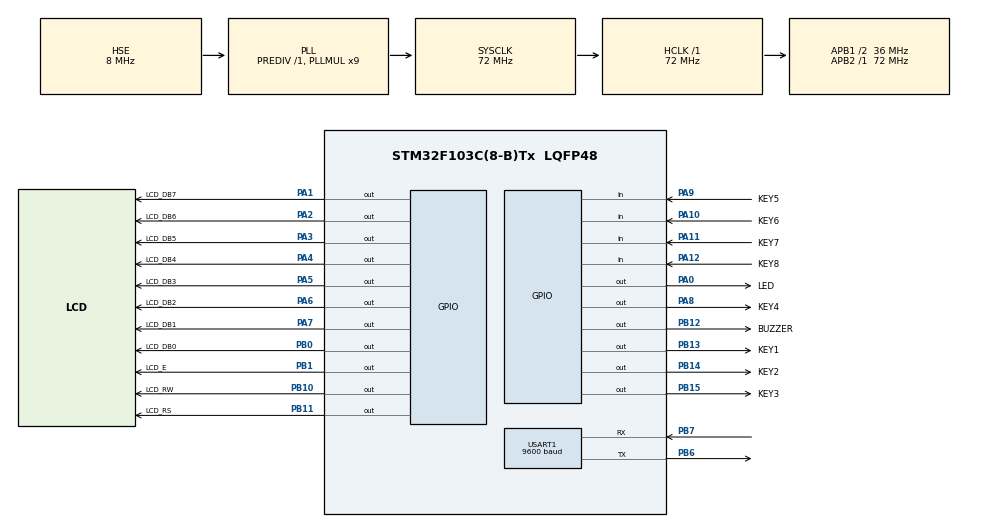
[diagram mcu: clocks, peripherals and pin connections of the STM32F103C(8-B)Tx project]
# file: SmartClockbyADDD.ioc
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Dma.Request0=USART1_RX
Dma.Request1=USART1_TX
Dma.USART1_RX.0.Direction=DMA_PERIPH_TO_MEMORY
Dma.USART1_RX.0.Instance=DMA1_Channel5
Dma.USART1_RX.0.MemDataAlignment=DMA_MDATAALIGN_BYTE
Dma.USART1_RX.0.MemInc=DMA_MINC_ENABLE
Dma.USART1_RX.0.Mode=DMA_NORMAL
Dma.USART1_RX.0.PeriphDataAlignment=DMA_PDATAALIGN_BYTE
Dma.USART1_RX.0.PeriphInc=DMA_PINC_DISABLE
Dma.USART1_RX.0.Priority=DMA_PRIORITY_LOW
Dma.USART1_TX.1.Direction=DMA_MEMORY_TO_PERIPH
Dma.USART1_TX.1.Instance=DMA1_Channel4
Dma.USART1_TX.1.MemDataAlignment=DMA_MDATAALIGN_BYTE
Dma.USART1_TX.1.MemInc=DMA_MINC_ENABLE
Dma.USART1_TX.1.Mode=DMA_NORMAL
Dma.USART1_TX.1.PeriphDataAlignment=DMA_PDATAALIGN_BYTE
Dma.USART1_TX.1.PeriphInc=DMA_PINC_DISABLE
Dma.USART1_TX.1.Priority=DMA_PRIORITY_LOW
Mcu.Family=STM32F1
Mcu.Name=STM32F103C(8-B)Tx
Mcu.Package=LQFP48
NVIC.DMA1_Channel4_IRQn=true\:0\:0\:false\:false\:true\:false\:true\:true
NVIC.DMA1_Channel5_IRQn=true\:0\:0\:false\:false\:true\:false\:true\:true
NVIC.PriorityGroup=NVIC_PRIORITYGROUP_4
NVIC.TIM4_IRQn=true\:0\:0\:false\:false\:true\:true\:true\:true
NVIC.USART1_IRQn=true\:0\:0\:false\:false\:true\:true\:true\:true
PA0-WKUP.GPIO_Label=LED
PA0-WKUP.GPIO_ModeDefaultOutputPP=GPIO_MODE_OUTPUT_OD
PA0-WKUP.GPIO_PuPd=GPIO_NOPULL
PA0-WKUP.Signal=GPIO_Output
PA1.GPIO_Label=LCD_DB7
PA1.Signal=GPIO_Output
PA10.GPIO_Label=KEY6
PA10.GPIO_PuPd=GPIO_PULLUP
PA10.Signal=GPIO_Input
PA11.GPIO_Label=KEY7
PA11.GPIO_PuPd=GPIO_PULLUP
PA11.Signal=GPIO_Input
PA12.GPIO_Label=KEY8
PA12.GPIO_PuPd=GPIO_PULLUP
PA12.Signal=GPIO_Input
PA13.Mode=Serial_Wire
PA13.Signal=SYS_JTMS-SWDIO
PA14.Mode=Serial_Wire
PA14.Signal=SYS_JTCK-SWCLK
PA2.GPIO_Label=LCD_DB6
PA2.Signal=GPIO_Output
PA3.GPIO_Label=LCD_DB5
PA3.Signal=GPIO_Output
PA4.GPIO_Label=LCD_DB4
PA4.Signal=GPIO_Output
PA5.GPIO_Label=LCD_DB3
PA5.Signal=GPIO_Output
PA6.GPIO_Label=LCD_DB2
PA6.Signal=GPIO_Output
PA7.GPIO_Label=LCD_DB1
PA7.Signal=GPIO_Output
PA8.GPIO_Label=KEY4
PA8.Signal=GPIO_Output
PA9.GPIO_Label=KEY5
PA9.GPIO_PuPd=GPIO_PULLUP
PA9.Signal=GPIO_Input
PB0.GPIO_Label=LCD_DB0
PB0.Signal=GPIO_Output
PB1.GPIO_Label=LCD_E
PB1.Signal=GPIO_Output
PB10.GPIO_Label=LCD_RW
PB10.Signal=GPIO_Output
PB11.GPIO_Label=LCD_RS
PB11.Signal=GPIO_Output
PB12.GPIO_Label=BUZZER
PB12.PinState=GPIO_PIN_SET
PB12.Signal=GPIO_Output
PB13.GPIO_Label=KEY1
PB13.Signal=GPIO_Output
PB14.GPIO_Label=KEY2
PB14.Signal=GPIO_Output
PB15.GPIO_Label=KEY3
PB15.Signal=GPIO_Output
PB6.Mode=Asynchronous
PB6.Signal=USART1_TX
PB7.Mode=Asynchronous
PB7.Signal=USART1_RX
PC14-OSC32_IN.Mode=LSE-External-Oscillator
PC14-OSC32_IN.Signal=RCC_OSC32_IN
PC15-OSC32_OUT.Mode=LSE-External-Oscillator
PC15-OSC32_OUT.Signal=RCC_OSC32_OUT
PD0-OSC_IN.Mode=HSE-External-Oscillator
PD0-OSC_IN.Signal=RCC_OSC_IN
PD1-OSC_OUT.Mode=HSE-External-Oscillator
PD1-OSC_OUT.Signal=RCC_OSC_OUT
ProjectManager.HeapSize=0x200
ProjectManager.StackSize=0x400
ProjectManager.TargetToolchain=STM32CubeIDE
RCC.AHBFreq_Value=72000000
RCC.APB1CLKDivider=RCC_HCLK_DIV2
RCC.APB1Freq_Value=36000000
RCC.APB1TimFreq_Value=72000000
RCC.APB2Freq_Value=72000000
RCC.APB2TimFreq_Value=72000000
RCC.HCLKFreq_Value=72000000
RCC.PLLMUL=RCC_PLL_MUL9
RCC.PLLSourceVirtual=RCC_PLLSOURCE_HSE
RCC.RTCClockSelection=RCC_RTCCLKSOURCE_LSE
RCC.SYSCLKFreq_VALUE=72000000
RCC.SYSCLKSource=RCC_SYSCLKSOURCE_PLLCLK
RCC.USBFreq_Value=72000000
TIM4.Period=1000-1
TIM4.Prescaler=720-1
USART1.BaudRate=9600
USART1.VirtualMode=VM_ASYNC
VP_RTC_VS_RTC_Activate.Mode=RTC_Enabled
VP_TIM4_VS_ClockSourceINT.Mode=Internal
board=custom

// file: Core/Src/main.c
/* USER CODE BEGIN Header */
/**
  ******************************************************************************
  * @file           : main.c
  * @brief          : Main program body
  ******************************************************************************
  * @attention
  *
  * Copyright (c) 2025 STMicroelectronics.
  * All rights reserved.
  *
  * This software is licensed under terms that can be found in the LICENSE file
  * in the root directory of this software component.
  * If no LICENSE file comes with this software, it is provided AS-IS.
  *
  ******************************************************************************
  */
/* USER CODE END Header */
#include "main.h"
#include "dma.h"
#include "rtc.h"
#include "tim.h"
#include "usart.h"
#include "gpio.h"

/* USER CODE BEGIN Includes */
#include "task_main.h"
//#include "test.h"
/* USER CODE END Includes */

void SystemClock_Config(void);

int main(void)
{

  /* MCU Configuration--------------------------------------------------------*/

  /* Reset of all peripherals, Initializes the Flash interface and the Systick. */
  HAL_Init();

  /* Configure the system clock */
  SystemClock_Config();

  /* Initialize all configured peripherals */
  MX_GPIO_Init();
  MX_DMA_Init();
  MX_RTC_Init();
  MX_USART1_UART_Init();
  MX_TIM4_Init();
  /* USER CODE BEGIN 2 */
  MainTaskInit();
  HAL_Delay(20);
  /* USER CODE END 2 */

  /* Infinite loop */
  /* USER CODE BEGIN WHILE */
  while (1)
  {
	  MainTask();
	  HAL_Delay(20);
    /* USER CODE END WHILE */

  }
}

void SystemClock_Config(void)
{
  RCC_OscInitTypeDef RCC_OscInitStruct = {0};
  RCC_ClkInitTypeDef RCC_ClkInitStruct = {0};
  RCC_PeriphCLKInitTypeDef PeriphClkInit = {0};

  /** Initializes the RCC Oscillators according to the specified parameters
  * in the RCC_OscInitTypeDef structure.
  */
  RCC_OscInitStruct.OscillatorType = RCC_OSCILLATORTYPE_HSE|RCC_OSCILLATORTYPE_LSE;
  RCC_OscInitStruct.HSEState = RCC_HSE_ON;
  RCC_OscInitStruct.HSEPredivValue = RCC_HSE_PREDIV_DIV1;
  RCC_OscInitStruct.LSEState = RCC_LSE_ON;
  RCC_OscInitStruct.HSIState = RCC_HSI_ON;
  RCC_OscInitStruct.PLL.PLLState = RCC_PLL_ON;
  RCC_OscInitStruct.PLL.PLLSource = RCC_PLLSOURCE_HSE;
  RCC_OscInitStruct.PLL.PLLMUL = RCC_PLL_MUL9;
  if (HAL_RCC_OscConfig(&RCC_OscInitStruct) != HAL_OK)
  {
    Error_Handler();
  }

  /** Initializes the CPU, AHB and APB buses clocks
  */
  RCC_ClkInitStruct.ClockType = RCC_CLOCKTYPE_HCLK|RCC_CLOCKTYPE_SYSCLK
                              |RCC_CLOCKTYPE_PCLK1|RCC_CLOCKTYPE_PCLK2;
  RCC_ClkInitStruct.SYSCLKSource = RCC_SYSCLKSOURCE_PLLCLK;
  RCC_ClkInitStruct.AHBCLKDivider = RCC_SYSCLK_DIV1;
  RCC_ClkInitStruct.APB1CLKDivider = RCC_HCLK_DIV2;
  RCC_ClkInitStruct.APB2CLKDivider = RCC_HCLK_DIV1;

  if (HAL_RCC_ClockConfig(&RCC_ClkInitStruct, FLASH_LATENCY_2) != HAL_OK)
  {
    Error_Handler();
  }
  PeriphClkInit.PeriphClockSelection = RCC_PERIPHCLK_RTC;
  PeriphClkInit.RTCClockSelection = RCC_RTCCLKSOURCE_LSE;
  if (HAL_RCCEx_PeriphCLKConfig(&PeriphClkInit) != HAL_OK)
  {
    Error_Handler();
  }
}

void Error_Handler(void)
{
  __disable_irq();
  while (1)
  {
  }
}
